# STM32L422 register map
File version: 1.0
CPU: CM4 r0p1, little endian, MPU, FPU, 4 interrupt priority bits
Registers are 32-bit, read-write, reset 0x0 unless marked. A register's access mark holds for its fields unless they carry their own. Offsets are from the block's base; [hi:lo] are bit positions; {n}, {i} and the like mark numbered series.

## USB_SRAM — Universal serial bus full-speed device interface
Base 0x40006C00
Same registers: USB_FS 0x40006800
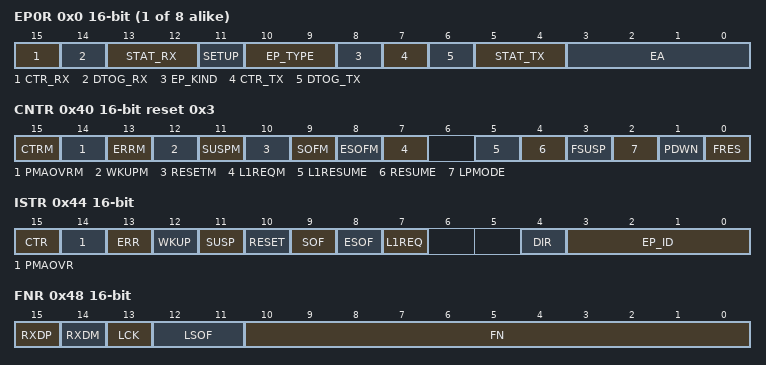
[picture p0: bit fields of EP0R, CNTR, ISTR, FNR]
{0x0+4i} EP{i}R 16-bit (i=0..7) — endpoint {i} register
  [15] CTR_RX — Correct transfer for reception
  [14] DTOG_RX — Data Toggle, for reception transfers
  [13:12] STAT_RX — Status bits, for reception transfers
  [11] SETUP — Setup transaction completed
  [10:9] EP_TYPE — Endpoint type
  [8] EP_KIND — Endpoint kind
  [7] CTR_TX — Correct Transfer for transmission
  [6] DTOG_TX — Data Toggle, for transmission transfers
  [5:4] STAT_TX — Status bits, for transmission transfers
  [3:0] EA — Endpoint address
0x40 CNTR 16-bit reset 0x3 — control register
  [15] CTRM — Correct transfer interrupt mask
  [14] PMAOVRM — Packet memory area over / underrun interrupt mask
  [13] ERRM — Error interrupt mask
  [12] WKUPM — Wakeup interrupt mask
  [11] SUSPM — Suspend mode interrupt mask
  [10] RESETM — USB reset interrupt mask
  [9] SOFM — Start of frame interrupt mask
  [8] ESOFM — Expected start of frame interrupt mask
  [7] L1REQM — LPM L1 state request interrupt mask
  [5] L1RESUME — LPM L1 Resume request
  [4] RESUME — Resume request
  [3] FSUSP — Force suspend
  [2] LPMODE — Low-power mode
  [1] PDWN — Power down
  [0] FRES — Force USB Reset
0x44 ISTR 16-bit access per field — interrupt status register
  [15] CTR ro — Correct transfer
  [14] PMAOVR rw — Packet memory area over / underrun
  [13] ERR rw — Error
  [12] WKUP rw — Wakeup
  [11] SUSP rw — Suspend mode request
  [10] RESET rw — reset request
  [9] SOF rw — start of frame
  [8] ESOF rw — Expected start frame
  [7] L1REQ rw — LPM L1 state request
  [4] DIR ro — Direction of transaction
  [3:0] EP_ID ro — Endpoint Identifier
0x48 FNR 16-bit ro — frame number register
  [15] RXDP — Receive data + line status
  [14] RXDM — Receive data - line status
  [13] LCK — Locked
  [12:11] LSOF — Lost SOF
  [10:0] FN — Frame number
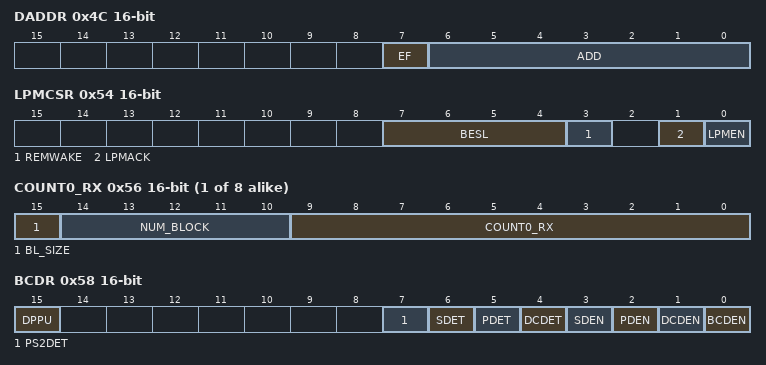
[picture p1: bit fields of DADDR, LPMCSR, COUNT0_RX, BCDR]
0x4C DADDR 16-bit — device address
  [7] EF — Enable function
  [6:0] ADD — Device address
0x50 BTABLE 16-bit — Buffer table address
  [15:3] BTABLE — Buffer table
{0x52+8i} COUNT{i}_TX 16-bit (i=0..7) — Transmission byte count 0
  [9:0] COUNT{i}_TX — Transmission byte count
0x54 LPMCSR 16-bit access per field — LPM control and status register
  [7:4] BESL ro — BESL value
  [3] REMWAKE ro — RemoteWake value
  [1] LPMACK rw — LPM Token acknowledge enable
  [0] LPMEN rw — LPM support enable
0x54 ADDR0_RX 16-bit (alternate view of LPMCSR) — Reception buffer address 0
  [15:1] ADDR0_RX — Reception buffer address
{0x56+8i} COUNT{i}_RX 16-bit access per field (i=0..7) — Reception byte count 0
  [15] BL_SIZE rw — Block size
  [14:10] NUM_BLOCK rw — Number of blocks
  [9:0] COUNT{i}_RX ro — Reception byte count
0x58 BCDR 16-bit access per field — Battery charging detector
  [15] DPPU rw — DP pull-up control
  [7] PS2DET ro — DM pull-up detection status
  [6] SDET ro — Secondary detection (SD) status
  [5] PDET ro — Primary detection (PD) status
  [4] DCDET ro — Data contact detection (DCD) status
  [3] SDEN rw — Secondary detection (SD) mode enable
  [2] PDEN rw — Primary detection (PD) mode enable
  [1] DCDEN rw — Data contact detection (DCD) mode enable
  [0] BCDEN rw — Battery charging detector (BCD) enable
{0x54+8i} ADDR{i}_RX 16-bit (i=1..7) — Reception buffer address 0
  [15:1] ADDR{i}_RX — Reception buffer address
0x60 ADDR2_TX 16-bit — Transmission buffer address 2
  [15:1] ADDR2_TX — Transmission buffer address
0x68 ADDR3_TX 16-bit — Transmission buffer address 3
  [15:1] ADDR3_TX — Transmission buffer address
0x70 ADDR4_TX 16-bit — Transmission buffer address 0
  [15:1] ADDR4_RX — Transmission buffer address
{0x50+8i} ADDR{i}_TX 16-bit (i=5..7) — Transmission buffer address 0
  [15:1] ADDR{i}_TX — Transmission buffer address
